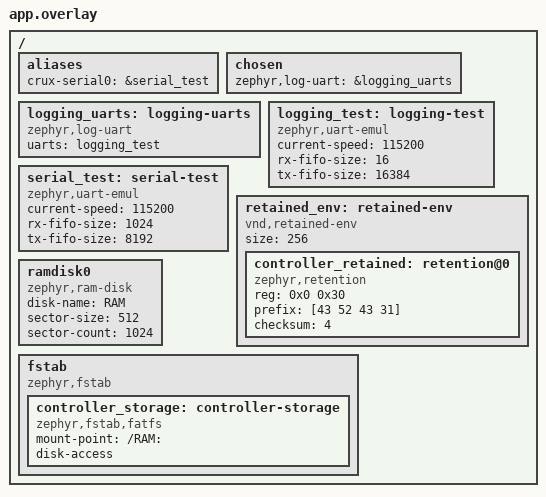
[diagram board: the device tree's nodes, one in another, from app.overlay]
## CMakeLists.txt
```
# SPDX-License-Identifier: Apache-2.0

# The recovery scenario of the controller framework on native_sim: the base composition with the
# simulated watchdog of Crux System, a retained region that survives the restart of the simulated
# process, and fault injection, over six boots of one run. The framework is the Zephyr module of
# this repository, turned on by CONFIG_CRUX_CONTROLLER_FRAMEWORK in prj.conf; this file names no
# source or include directory of the module. The test-only retained memory and the helpers of the
# scenarios are in ../common.

cmake_minimum_required(VERSION 3.20.0)
list(APPEND DTS_ROOT "${CMAKE_CURRENT_LIST_DIR}/../common")
find_package(Zephyr REQUIRED HINTS $ENV{ZEPHYR_BASE})
project(controller_framework_recovery_native_sim LANGUAGES C)

if(NOT CONFIG_BOARD_NATIVE_SIM OR NOT CONFIG_FAKE_ENTROPY_NATIVE_SIM)
    message(FATAL_ERROR "This scenario is restricted to native_sim: its entropy source is a test source")
endif()
if(NOT CONFIG_CRUX_CONTROLLER_FRAMEWORK_SUPERVISION OR NOT CONFIG_CRUX_CONTROLLER_FRAMEWORK_REBOOT
   OR NOT CONFIG_CRUX_CONTROLLER_FRAMEWORK_FAULT_INJECTION OR NOT CONFIG_CRUX_SYSTEM_NATIVE_SIM_WATCHDOG)
    message(FATAL_ERROR "The recovery scenario needs supervision, Crux Reboot, fault injection and the simulated watchdog")
endif()

target_sources(app PRIVATE src/test_recovery.c ../common/scenario.c ../common/retained_env.c)
target_include_directories(app PRIVATE ../common)
target_link_libraries(app PRIVATE controller::framework)
controller_framework_image()
```

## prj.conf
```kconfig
# The recovery scenario of the controller framework on native_sim (criteria 7, 11, 16 and 17): the
# base composition of tests/framework/base/prj.conf, with the simulated watchdog of Crux System,
# which restarts the simulated process after a missed feed (gap C11), a retained region over the
# test-only retained memory of ../common, and fault injection. The program of src/test_recovery.c runs six
# boots in one run and prints what Twister's console harness matches (testcase.yaml).
CONFIG_CRUX_CONTROLLER_FRAMEWORK=y
CONFIG_SNTP=y
CONFIG_CRUX_CONTROLLER_TIME_SERVER="127.0.0.1"

CONFIG_CRUX_SERIAL=y
CONFIG_CRUX_CLI=y
CONFIG_CRUX_CLI_CONSOLE=y
CONFIG_CRUX_CLI_CONSOLE_PRIORITY=11
CONFIG_UART_INTERRUPT_DRIVEN=y
CONFIG_UART_USE_RUNTIME_CONFIGURE=y

CONFIG_STD_C17=y
CONFIG_EMUL=y
CONFIG_UART_EMUL=y
CONFIG_IRQ_OFFLOAD=y
# The web adapter refuses the external libc of native_sim; the management scenario runs on picolibc.
CONFIG_PICOLIBC=y
# One thread of the test runs the start sequence (key generation, signing, the format of the RAM
# disk) and the TLS client. Not measured.
CONFIG_MAIN_STACK_SIZE=32768
CONFIG_HEAP_MEM_POOL_SIZE=32768

# The Mbed TLS profile of app/conf/management.conf, as a copy: this scenario has no Kconfig of the product,
# as in the management scenario. The heap is larger than the product's 120,000 bytes,
# because the TLS client of the test runs in the same process and takes up to one more connection
# and its own handshake. The product declares 120,000 bytes for three server connections of 34,912
# bytes, a handshake of 3,576 bytes and the other PSA users, and 180,000 leaves about 25,000 bytes
# over the worst concurrent case that this process can reach. A paper figure, not measured.
CONFIG_MBEDTLS=y
CONFIG_MBEDTLS_PSA_CRYPTO_C=y
CONFIG_PSA_CRYPTO_PROVIDER_MBEDTLS=y
CONFIG_MBEDTLS_ENABLE_HEAP=y
CONFIG_MBEDTLS_HEAP_SIZE=180000
CONFIG_MBEDTLS_SSL_IN_CONTENT_LEN=16384
CONFIG_MBEDTLS_SSL_OUT_CONTENT_LEN=16384
CONFIG_MBEDTLS_SSL_PROTO_TLS1_2=y
CONFIG_MBEDTLS_SSL_PROTO_TLS1_3=y
CONFIG_MBEDTLS_SSL_TLS1_3_KEY_EXCHANGE_MODE_EPHEMERAL_ENABLED=y
CONFIG_MBEDTLS_KEY_EXCHANGE_ECDHE_ECDSA_ENABLED=y
CONFIG_MBEDTLS_CIPHERSUITE_TLS_ECDHE_ECDSA_WITH_AES_128_GCM_SHA256=y
CONFIG_MBEDTLS_CIPHERSUITE_TLS1_3_AES_128_GCM_SHA256=y
CONFIG_PSA_WANT_ALG_SHA_256=y
CONFIG_PSA_WANT_ECC_SECP_R1_256=y
CONFIG_PSA_WANT_ALG_ECDSA=y
CONFIG_PSA_WANT_ALG_ECDH=y
CONFIG_PSA_WANT_ALG_GCM=y
CONFIG_PSA_WANT_KEY_TYPE_AES=y
CONFIG_PSA_WANT_ALG_HMAC=y
CONFIG_PSA_WANT_KEY_TYPE_HMAC=y
CONFIG_PSA_WANT_ALG_HKDF=y
CONFIG_PSA_WANT_ALG_PBKDF2_HMAC=y
CONFIG_PSA_WANT_ALG_TLS12_PRF=y
CONFIG_PSA_WANT_KEY_TYPE_ECC_PUBLIC_KEY=y
CONFIG_PSA_WANT_KEY_TYPE_ECC_KEY_PAIR_IMPORT=y
CONFIG_PSA_WANT_KEY_TYPE_ECC_KEY_PAIR_EXPORT=y
CONFIG_PSA_WANT_KEY_TYPE_ECC_KEY_PAIR_GENERATE=y
CONFIG_PSA_WANT_KEY_TYPE_ECC_KEY_PAIR_DERIVE=y
CONFIG_MBEDTLS_PK_WRITE_C=y
CONFIG_CRUX_PSA_THREADING=y

# The Crux services, as in app/conf/management.conf. The module selects Thread, Sync and Time for them.
CONFIG_CRUX_ACCESS=y
CONFIG_CRUX_CONFIG_SERVICE=y
CONFIG_CRUX_MGMT_STATUS=y
CONFIG_CRUX_TLS_CERTIFICATE=y
CONFIG_CRUX_WEB=y
CONFIG_CRUX_WEB_SESSION=y
CONFIG_CRUX_WEB_MANAGEMENT=y
CONFIG_CRUX_SYSTEM=y
CONFIG_CRUX_NETIF=y
CONFIG_WATCHDOG=y
CONFIG_HWINFO=y
CONFIG_REBOOT=y

# The listener binds the loopback address, and the TLS client of the test is in the same process. The
# listener opens on Zephyr's own thread, so the client retries its connect.
CONFIG_CRUX_WEB_PORT=443
CONFIG_CRUX_WEB_BIND_ADDRESS="127.0.0.1"
CONFIG_CRUX_WEB_BACKLOG=4
CONFIG_HTTP_SERVER_MAX_CLIENTS=3
CONFIG_HTTP_SERVER_STACK_SIZE=16384
CONFIG_CRUX_WEB_SESSION_WORKER_PRIORITY=11
CONFIG_CRUX_WEB_MANAGEMENT_WORKER_PRIORITY=11
CONFIG_CRUX_SECURITY_EVENT_DRAIN_PRIORITY=11

# The simulator's fake entropy source: test-only, so nothing made here is a secret.
CONFIG_ENTROPY_GENERATOR=y

# Crux File on a RAM disk with the simulator provider, and the formatting service that the zone
# uses when the blank disk does not mount.
CONFIG_FILE_SYSTEM=y
CONFIG_FILE_SYSTEM_MKFS=y
CONFIG_FAT_FILESYSTEM_ELM=y
CONFIG_FS_FATFS_LFN=y
CONFIG_FS_FATFS_LFN_MODE_STACK=y
CONFIG_FS_FATFS_MAX_LFN=127
CONFIG_FS_FATFS_MOUNT_MKFS=n
CONFIG_FS_FATFS_REENTRANT=y
CONFIG_FS_FATFS_NUM_FILES=6
CONFIG_DISK_DRIVERS=y
CONFIG_DISK_DRIVER_RAM=y
CONFIG_CRUX_FILE_FATFS_SIMULATOR=y

# The network: Zephyr's loopback interface, TCP and the TLS socket layer, with no host network.
CONFIG_NETWORKING=y
CONFIG_NET_IPV4=y
CONFIG_NET_IPV6=n
CONFIG_NET_TCP=y
CONFIG_NET_UDP=y
CONFIG_NET_SOCKETS=y
CONFIG_NET_DRIVERS=y
CONFIG_NET_LOOPBACK=y
CONFIG_NET_SOCKETS_SOCKOPT_TLS=y
CONFIG_TLS_CREDENTIALS=y
CONFIG_TLS_MAX_CREDENTIALS_NUMBER=4
CONFIG_NET_SOCKETS_TLS_MAX_CONTEXTS=6
CONFIG_ZVFS_OPEN_MAX=48
CONFIG_ZVFS_POLL_MAX=24
CONFIG_ZVFS_EVENTFD=y
CONFIG_NET_MAX_CONTEXTS=32
CONFIG_NET_MAX_CONN=32
CONFIG_NET_PKT_RX_COUNT=64
CONFIG_NET_PKT_TX_COUNT=64
CONFIG_NET_BUF_RX_COUNT=256
CONFIG_NET_BUF_TX_COUNT=256

# Crux Logging writes to an emulated UART, so that the test can read what it wrote.
CONFIG_CRUX_LOGGING=y
CONFIG_SERIAL=y
CONFIG_LOG=y
CONFIG_LOG_MODE_DEFERRED=y
CONFIG_LOG_MODE_OVERFLOW=n
CONFIG_LOG_BLOCK_IN_THREAD=n
CONFIG_LOG_PROCESS_THREAD=y
CONFIG_LOG_PROCESS_THREAD_STACK_SIZE=2048
CONFIG_LOG_PROCESS_THREAD_CUSTOM_PRIORITY=y
CONFIG_LOG_PROCESS_THREAD_PRIORITY=14
CONFIG_LOG_BUFFER_SIZE=8192
CONFIG_LOG_MAX_LEVEL=4
CONFIG_LOG_DEFAULT_LEVEL=0
CONFIG_LOG_RUNTIME_FILTERING=n
CONFIG_LOG_BACKEND_UART=y
CONFIG_LOG_BACKEND_NATIVE_POSIX=n
CONFIG_LOG_BACKEND_UART_ASYNC=n
CONFIG_LOG_PRINTK=n
CONFIG_SHELL_LOG_BACKEND=n
CONFIG_LOG_BACKEND_SHOW_LEVEL=y
CONFIG_LOG_BACKEND_CRLF_NONE=n
CONFIG_THREAD_MONITOR=y
CONFIG_THREAD_NAME=y
# An image with Crux management must not enable the Zephyr shell.
CONFIG_SHELL=n

# Health supervision with the simulated watchdog and the retained region, short timeouts so that
# the scenario stays short, and fault injection. The retained memory and the retention area are
# built without their mutexes, as the base image builds them, because the fatal error handler
# writes the region.
CONFIG_TASK_WDT=y
CONFIG_TASK_WDT_HW_FALLBACK=n
CONFIG_CRUX_REBOOT=y
CONFIG_CRUX_SYSTEM_NATIVE_SIM_WATCHDOG=y
CONFIG_NATIVE_SIM_REBOOT=y
CONFIG_RETAINED_MEM=y
CONFIG_RETAINED_MEM_MUTEX_FORCE_DISABLE=y
CONFIG_RETENTION=y
CONFIG_RETENTION_MUTEX_FORCE_DISABLE=y
CONFIG_CRUX_CONTROLLER_FRAMEWORK_FAULT_INJECTION=y
CONFIG_CRUX_CONTROLLER_WATCHDOG_TIMEOUT_MS=2000
# A short reload of the Crux service threads' channels, so that boot 6 sees the web session worker's
# channel expire within the scenario's time; a value other than the default (criterion 27).
CONFIG_CRUX_CONTROLLER_SERVICE_RELOAD_MS=3000
CONFIG_CRUX_CONTROLLER_SUPERVISOR_PERIOD_MS=500
CONFIG_CRUX_CONTROLLER_DEADLINE_COMMAND_LINE_MS=2000
CONFIG_CRUX_CONTROLLER_STABLE_PERIOD_S=3600
CONFIG_MAIN_THREAD_PRIORITY=8
```

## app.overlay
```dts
/* The devicetree of the base scenario (tests/framework/base/app.overlay), with a retained region
 * over the test-only retained memory of ../common, which keeps its bytes across a restart of the
 * simulated process, as boards/retained.overlay places the region for the board.
 *
 * From the devicetree of the management scenario (tests/native_sim_mbed/management/app.overlay):
 * Crux Logging writes to an emulated UART here, so that the test can read what it wrote. The RAM
 * disk and the fstab entry are the ones that boards/management.overlay declares for the board, with the
 * same names, because the composition zone looks up the entry controller_storage. The disk is
 * blank at every start: the zone formats it. The Crux serial console owns a second emulated UART
 * through the alias crux-serial0: the test types into its receive side and reads its transmit
 * side. */
/ {
    aliases { crux-serial0 = &serial_test; };
    chosen { zephyr,log-uart = &logging_uarts; };
    logging_uarts: logging-uarts {
        compatible = "zephyr,log-uart";
        uarts = <&logging_test>;
    };
    logging_test: logging-test {
        compatible = "zephyr,uart-emul";
        current-speed = <115200>;
        rx-fifo-size = <16>;
        tx-fifo-size = <16384>;
        status = "okay";
    };
    serial_test: serial-test {
        compatible = "zephyr,uart-emul";
        current-speed = <115200>;
        rx-fifo-size = <1024>;
        /* The status command writes more than 1 KiB at once, and the emulated UART drops the bytes
         * that do not fit (uart_emul_poll_out in Zephyr's drivers/serial/uart_emul.c). */
        tx-fifo-size = <8192>;
        status = "okay";
    };

    retained_env: retained-env {
        compatible = "vnd,retained-env";
        size = <256>;
        status = "okay";
        #address-cells = <1>;
        #size-cells = <1>;

        controller_retained: retention@0 {
            compatible = "zephyr,retention";
            status = "okay";
            reg = <0x0 0x30>;
            prefix = [43 52 43 31];
            checksum = <4>;
        };
    };

    ramdisk0 {
        compatible = "zephyr,ram-disk";
        disk-name = "RAM";
        sector-size = <512>;
        sector-count = <1024>;
    };

    fstab {
        compatible = "zephyr,fstab";
        controller_storage: controller-storage {
            compatible = "zephyr,fstab,fatfs";
            mount-point = "/RAM:";
            disk-access;
        };
    };
};
```

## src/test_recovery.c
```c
/* SPDX-License-Identifier: Apache-2.0 */

/* The recovery scenario of the controller framework on native_sim. One run, seven boots: the
 * simulated watchdog of Crux System restarts the simulated process after a missed feed, which
 * then reads the reset cause SOFTWARE (gap C11), and the retained region over the test-only
 * retained memory of ../common survives the restart. Each boot arms one fault, starts the framework
 * and prints what the console harness of testcase.yaml matches, in order:
 *
 *   1. A startup step stalls past its deadline: the supervisor stops feeding and the simulated
 *      watchdog restarts the image (criterion 7).
 *   2. The record names the step and the reset counts (counter 1). The supervisor thread raises a
 *      fatal error: the handler writes the minimal record and restarts the image (criterion 16).
 *   3. The record names the fatal error and the reset counts (counter 2). The time synchronisation
 *      thread stops feeding its channel: the expiry is recorded and the image restarts.
 *   4. Counter 3 = N: safe mode, with no time synchronisation and no application. The framework's
 *      reboot thread, a safe-mode service, stalls: the image restarts (criterion 17).
 *   5. Safe mode again, the counter saturated. Device management answers: first-account setup and
 *      a login over the serial command line, and the status command shows the recovery state; the
 *      recovery exit command clears the counter and restarts through Crux Reboot with the operator
 *      reset marker (criterion 11).
 *   6. A normal boot: the marker makes the reset a planned one, and the counter is zero. The
 *      reports of the Crux web session worker stop feeding its channel: the expiry is recorded and
 *      the image restarts (criterion 33).
 *   7. The record names the web session worker's channel and the reset counts (counter 1).
 *
 * The base image has no application, so "the application is not initialised" of criterion 11 shows
 * as "no application: safe mode"; the fixture application of delivery stage 3 shows the rest. */

#include <stdbool.h>
#include <stdio.h>

#include <controller/framework.h>
#include <controller/framework_test.h>
#include <zephyr/kernel.h>

#include "scenario.h"

#define USER "operator"
#define PASSWORD "recovery scenario password"

static void fail(const char *what)
{
    char text[160];

    (void)snprintf(text, sizeof text, "recovery scenario FAILED: %s", what);
    scenario_say(text);
}

static bool expect(const char *text)
{
    if (!scenario_console_expect(text)) {
        fail(text);
        return false;
    }
    return true;
}

/* Boot 5: set up the first account, log in, check the status and leave safe mode. */
static void leave_safe_mode(void)
{
    if (!expect("login: ")) {
        return;
    }
    scenario_console_type("!setup");
    if (!expect("new user: ")) {
        return;
    }
    scenario_console_type(USER);
    if (!expect("password: ")) {
        return;
    }
    scenario_console_type(PASSWORD);
    if (!expect("repeat: ")) {
        return;
    }
    scenario_console_type(PASSWORD);
    if (!expect("account created") || !expect("login: ")) {
        return;
    }
    scenario_console_type(USER);
    if (!expect("password: ")) {
        return;
    }
    scenario_console_type(PASSWORD);
    if (!expect("> ")) {
        return;
    }
    scenario_console_type("status");
    if (!expect("{\"name\":\"controller.state\",\"status\":\"ok\",\"type\":\"text\","
                "\"value\":\"recovery\"}") ||
        !expect("{\"name\":\"controller.safe_mode\",\"status\":\"ok\",\"type\":\"bool\","
                "\"value\":true}") ||
        !expect("{\"name\":\"controller.boot_counter\",\"status\":\"ok\",\"type\":\"u32\","
                "\"value\":3}") ||
        !expect("> ")) {
        return;
    }
    scenario_say("recovery scenario: status shows safe mode");
    scenario_console_type("recovery exit");
    if (!expect("restart requested")) {
        return;
    }
    scenario_say("recovery scenario: restart requested");
}

int main(void)
{
    char text[64];
    const int boot = scenario_boot_number();

    scenario_forward_log();
    (void)snprintf(text, sizeof text, "recovery scenario boot %d", boot);
    scenario_say(text);

    switch (boot) {
    case 1:
        (void)controller_framework_inject(CONTROLLER_FRAMEWORK_FAULT_STEP_STALL, "command line");
        break;
    case 2:
        (void)controller_framework_inject(CONTROLLER_FRAMEWORK_FAULT_FATAL, NULL);
        break;
    case 3:
        (void)controller_framework_inject(CONTROLLER_FRAMEWORK_FAULT_THREAD_STALL, "time");
        break;
    case 4:
        (void)controller_framework_inject(CONTROLLER_FRAMEWORK_FAULT_THREAD_STALL, "reboot");
        break;
    case 6:
        (void)controller_framework_inject(CONTROLLER_FRAMEWORK_FAULT_THREAD_STALL, "web session");
        break;
    default:
        break;
    }
    if (controller_framework_start(NULL) != CONTROLLER_FRAMEWORK_OK) {
        fail("the start function");
    }
    if (boot == 5) {
        leave_safe_mode();
    } else if (boot == 7) {
        scenario_say("recovery scenario done");
    } else if (boot > 7) {
        fail("more boots than planned");
    }
    for (;;) {
        k_sleep(K_FOREVER);
    }
    return 0;
}
```
